# STM32L4P5 register map
File version: 1.8
CPU: CM4 r0p1, little endian, MPU, FPU, 4 interrupt priority bits
Registers are 32-bit, read-write, reset 0x0 unless marked. A register's access mark holds for its fields unless they carry their own. Offsets are from the block's base; [hi:lo] are bit positions; 'fields as' and 'values as' point back to an identical list.

## OCTOSPI1 — OctoSPI
Base 0xA0001000
Same registers: OCTOSPI2 0xA0001400
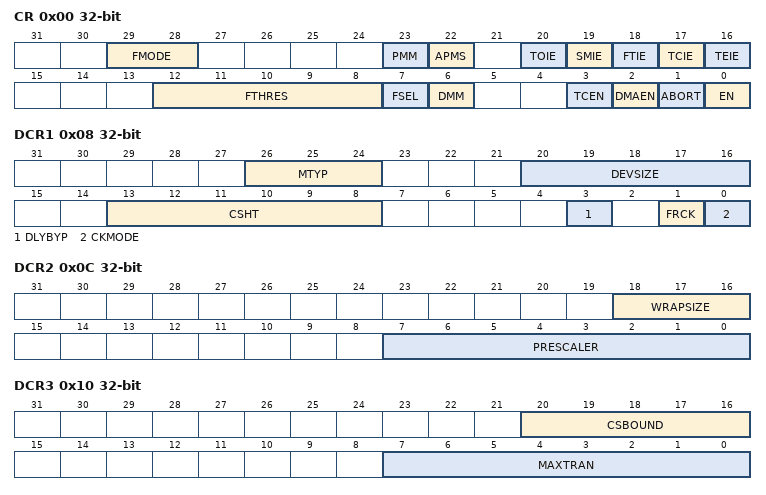
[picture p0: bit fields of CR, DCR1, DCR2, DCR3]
0x00 CR — control register
  [29:28] FMODE — Functional mode
    0=Indirect-write mode; 1=Indirect-read mode; 2=AutomaticPolling (Automatic status-polling mode); 3=Memory-mapped mode
  [23] PMM — Polling match mode
    0=AND-match mode, SMF is set if all the unmasked bits received from the device match the corresponding bits in the match register; 1=OR-match mode, SMF is set if any of the unmasked bits received from the device matches its corresponding bit in the match register
  [22] APMS — Automatic poll mode stop
    0=Running (Automatic status-polling mode is stopped only by abort or by disabling the OCTOSPI); 1=StopMatch (Automatic status-polling mode stops as soon as there is a match)
  [20] TOIE — TimeOut interrupt enable
    0=Disabled (Interrupt disabled); 1=Enabled (Interrupt enabled)
  [19] SMIE — Status match interrupt enable
    values as TOIE
  [18] FTIE — FIFO threshold interrupt enable
    values as TOIE
  [17] TCIE — Transfer complete interrupt enable
    values as TOIE
  [16] TEIE — Transfer error interrupt enable
    values as TOIE
  [12:8] FTHRES — IFO threshold level
  [7] FSEL — FLASH memory selection
    0=FLASH1 (FLASH 1 selected (data exchanged over IO[3:0])); 1=FLASH2 (FLASH 2 selected (data exchanged over IO[7:4]))
  [6] DMM — Dual-memory configuration
    0=Disabled (Dual-quad configuration disabled); 1=Enabled (Dual-quad configuration enabled)
  [3] TCEN — Timeout counter enable
    0=Disabled (Timeout counter is disabled, and thus the chip-select (NCS) remains active indefinitely after an access in Memory-mapped mode); 1=Enabled (Timeout counter is enabled, and thus the chip-select is released in the Memory-mapped mode after TIMEOUT[15:0] cycles of external device inactivity)
  [2] DMAEN — DMA enable
    0=Disabled (DMA disabled for Indirect mode); 1=Enabled (DMA enabled for Indirect mode)
  [1] ABORT — Abort request
    0=NotRequested (No abort requested); 1=Requested (Abort requested)
  [0] EN — Enable
    0=Disabled (OCTOSPI disabled); 1=Enabled (OCTOSPI enabled)
0x08 DCR1 — device configuration register
  [26:24] MTYP — Memory type
    0=Micron mode, D0/D1 ordering in DTR 8-data-bit mode. Regular-command protocol in Single-, Dual-, Quad- and Octal-SPI modes; 1=Macronix mode, D1/D0 ordering in DTR 8-data-bit mode. Regular-command protocol in Single-, Dual-, Quad- and Octal-SPI modes; 2=StandardMode; 3=Macronix RAM mode, D1/D0 ordering in DTR 8-data-bit mode. Regular-command protocol in Single-, Dual-, Quad- and Octal-SPI modes with dedicated address mapping; 4=HyperBus memory mode, the protocol follows the HyperBus specification. 8-data-bit DTR mode must be selected; 5=HyperBusMode (HyperBus register mode, addressing register space. The memory-mapped accesses in this mode must be non-cacheable, or Indirect read/write modes must be used)
  [20:16] DEVSIZE — Device size
  [13:8] CSHT — Chip-select high time
  [3] DLYBYP — Delay block bypass
    0=DelayBlockEnabled (The internal sampling clock (called feedback clock) or the DQS data strobe external signal is delayed by the delay block (for more details on this block, refer to the dedicated section of the reference manual as it is not part of the OCTOSPI peripheral)); 1=DelayBlockBypassed (The delay block is bypassed, so the internal sampling clock or the DQS data strobe external signal is not affected by the delay block. The delay is shorter than when the delay block is not bypassed, even with the delay value set to minimum value in delay block)
  [1] FRCK — Free running clock
    0=Disabled (CLK is not free running); 1=Enabled (CLK is free running (always provided))
  [0] CKMODE — Mode 0 / mode 3
    0=Mode0 (CLK must stay low while NCS is high (chip-select released). This is referred to as Mode 0); 1=Mode3 (CLK must stay high while NCS is high (chip-select released). This is referred to as Mode 3)
0x0C DCR2 — device configuration register 2
  [18:16] WRAPSIZE
    0=NoWrappingSupport (Wrapped reads are not supported by the memory); 2=WrappingSize16 (External memory supports wrap size of 16 bytes); 3=WrappingSize32 (External memory supports wrap size of 32 bytes); 4=WrappingSize64 (External memory supports wrap size of 64 bytes); 5=WrappingSize128 (External memory supports wrap size of 128 bytes)
  [7:0] PRESCALER — Clock prescaler
0x10 DCR3 — device configuration register 3
  [20:16] CSBOUND — CS boundary
  [7:0] MAXTRAN — Maximum transfer
0x14 DCR4 — device configuration register 4
  [31:0] REFRESH — Refresh rate
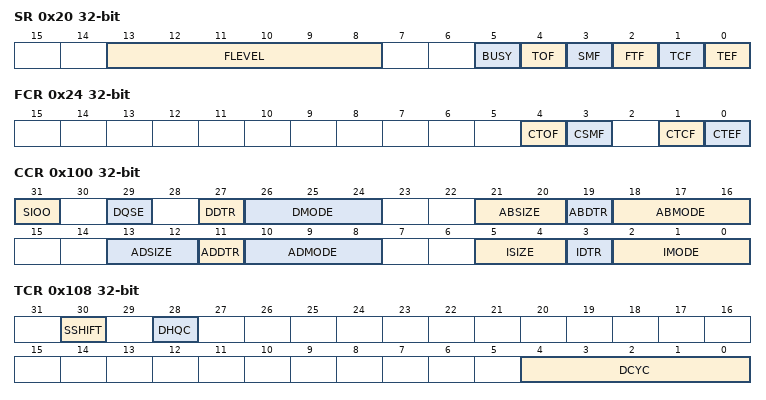
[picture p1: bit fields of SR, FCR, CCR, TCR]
0x20 SR ro — status register
  [13:8] FLEVEL — FIFO level
  [5] BUSY
    0=Cleared (This bit is cleared automatically when the operation with the external device is finished and the FIFO is empty); 1=Busy (This bit is set when an operation is ongoing)
  [4] TOF — Timeout flag
    0=Cleared (This bit is cleared by writing 1 to CTOF); 1=Timeout (This bit is set when timeout occurs)
  [3] SMF — Status match flag
    0=Cleared (It is cleared by writing 1 to CSMF); 1=Matched (This bit is set in Automatic status-polling mode when the unmasked received data matches the corresponding bits in the match register (OCTOSPI_PSMAR))
  [2] FTF — FIFO threshold flag
    0=Cleared (It is cleared automatically as soon as the threshold condition is no longer true); 1=ThresholdReached (This bit is set when the FIFO threshold has been reached)
  [1] TCF — Transfer complete flag
    0=Cleared (This bit is cleared by writing 1 to CTCF); 1=TransferCompleted (This bit is set when the programmed number of data has been transferred)
  [0] TEF — Transfer error flag
    0=Cleared (This bit is cleared by writing 1 to CTEF); 1=InvalidAddressAccessed (This bit is set in Indirect mode when an invalid address is being accessed in Indirect mode)
0x24 FCR wo — flag clear register
  [4] CTOF — Clear timeout flag
    1=Clear (Writing 1 clears the TOF flag in the OCTOSPI_SR register)
  [3] CSMF — Clear status match flag
    1=Clear (Writing 1 clears the SMF flag in the OCTOSPI_SR register)
  [1] CTCF — Clear transfer complete flag
    1=Clear (Writing 1 clears the TCF flag in the OCTOSPI_SR register)
  [0] CTEF — Clear transfer error flag
    1=Clear (Writing 1 clears the TEF flag in the OCTOSPI_SR register)
0x40 DLR — data length register
  [31:0] DL — Data length
0x48 AR — address register
  [31:0] ADDRESS
0x50 DR — data register
  [31:0] DATA
0x80 PSMKR — polling status mask register
  [31:0] MASK — Status mask
0x88 PSMAR — polling status match register
  [31:0] MATCH — Status match
0x90 PIR — polling interval register
  [15:0] INTERVAL — Polling interval
0x100 CCR — communication configuration register
  [31] SIOO — Send instruction only once mode
    0=SendEveryTransaction (Send instruction on every transaction); 1=SendOnlyFirstCmd (Send instruction only for the first command)
  [29] DQSE — DQS enable
    0=Disabled (DQS disabled); 1=Enabled (DQS enabled)
  [27] DDTR — Alternate bytes double transfer rate
    0=Disabled (DTR mode disabled for data phase); 1=Enabled (DTR mode enabled for data phase)
  [26:24] DMODE — Data mode
    0=NoData; 1=SingleLine (Data on a single line); 2=TwoLines (Data on two lines); 3=FourLines (Data on four lines); 4=EightLines (Data on eight lines)
  [21:20] ABSIZE — Alternate bytes size
    0=Bits8 (8-bit alternate bytes); 1=Bits16 (16-bit alternate bytes); 2=Bits24 (24-bit alternate bytes); 3=Bits32 (32-bit alternate bytes)
  [19] ABDTR — Alternate bytes double transfer rate
    0=Disabled (DTR mode disabled for alternate bytes phase); 1=Enabled (DTR mode enabled for alternate bytes phase)
  [18:16] ABMODE — Alternate byte mode
    0=NoAlternateBytes; 1=SingleLine (Alternate bytes on a single line); 2=TwoLines (Alternate bytes on two lines); 3=FourLines (Alternate bytes on four lines); 4=EightLines (Alternate bytes on eight lines)
  [13:12] ADSIZE — Address size
    0=Bits8 (8-bit address); 1=Bits16 (16-bit address); 2=Bits24 (24-bit address); 3=Bits32 (32-bit address)
  [11] ADDTR — Address double transfer rate
    0=Disabled (DTR mode disabled for address phase); 1=Enabled (DTR mode enabled for address phase)
  [10:8] ADMODE — Address mode
    0=NoAddress; 1=SingleLine (Address on a single line); 2=TwoLines (Address on two lines); 3=FourLines (Address on four lines); 4=EightLines (Address on eight lines)
  [5:4] ISIZE — Instruction size
    0=Bits8 (8-bit instruction); 1=Bits16 (16-bit instruction); 2=Bits24 (24-bit instruction); 3=Bits32 (32-bit instruction)
  [3] IDTR — Instruction double transfer rate
    0=Disabled (DTR mode disabled for instruction phase); 1=Enabled (DTR mode enabled for instruction phase)
  [2:0] IMODE — Instruction mode
    0=NoInstruction; 1=SingleLine (Instruction on a single line); 2=TwoLines (Instruction on two lines); 3=FourLines (Instruction on four lines); 4=EightLines (Instruction on eight lines)
0x108 TCR — timing configuration register
  [30] SSHIFT — Sample shift
    0=NoShift; 1=HalfCycleShift (1/2 cycle shift)
  [28] DHQC — Delay hold quarter cycle
    0=No delay hold; 1=QuarterCycleHold (1/4 cycle hold)
  [4:0] DCYC — Number of dummy cycles
0x110 IR — instruction register
  [31:0] INSTRUCTION
0x120 ABR — alternate bytes register
  [31:0] ALTERNATE — Alternate bytes
0x130 LPTR — low-power timeout register
  [15:0] TIMEOUT — Timeout period
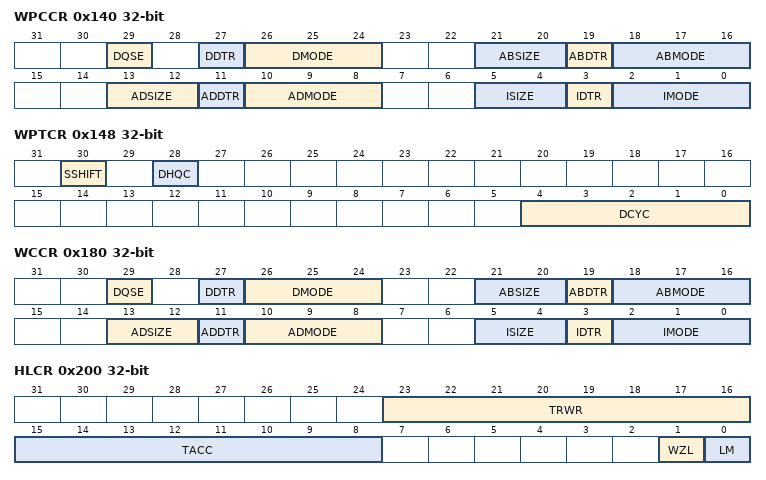
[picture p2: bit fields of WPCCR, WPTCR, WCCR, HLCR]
0x140 WPCCR access not given — wrap communication configuration register
  [29] DQSE — DQS enable
    0=Disabled (DQS disabled); 1=Enabled (DQS enabled)
  [27] DDTR — Data double transfer rate
    values as CCR.DDTR
  [26:24] DMODE — Data mode
    values as CCR.DMODE
  [21:20] ABSIZE — Alternate bytes size
    values as CCR.ABSIZE
  [19] ABDTR — Alternate bytes double transfer rate
    values as CCR.ABDTR
  [18:16] ABMODE — Alternate-byte mode
    values as CCR.ABMODE
  [13:12] ADSIZE — Address size
    values as CCR.ADSIZE
  [11] ADDTR — Address double transfer rate
    values as CCR.ADDTR
  [10:8] ADMODE — Address mode
    values as CCR.ADMODE
  [5:4] ISIZE — Instruction size
    values as CCR.ISIZE
  [3] IDTR — Instruction double transfer rate
    values as CCR.IDTR
  [2:0] IMODE — Instruction mode
    values as CCR.IMODE
0x148 WPTCR access not given — Wrap timing configuration register
  fields as TCR
0x150 WPIR access not given — Wrap instruction register
  [31:0] INSTRUCTION
0x160 WPABR access not given — Wrap alternate bytes register
  [31:0] ALTERNATE — Alternate bytes
0x180 WCCR — write communication configuration register
  [29] DQSE — DQS enable
    0=Disabled (DQS disabled); 1=Enabled (DQS enabled)
  [27] DDTR — alternate bytes double transfer rate
    values as CCR.DDTR
  [26:24] DMODE — Data mode
    values as CCR.DMODE
  [21:20] ABSIZE — Alternate bytes size
    values as CCR.ABSIZE
  [19] ABDTR — Alternate bytes double transfer rate
    values as CCR.ABDTR
  [18:16] ABMODE — Alternate byte mode
    values as CCR.ABMODE
  [13:12] ADSIZE — Address size
    values as CCR.ADSIZE
  [11] ADDTR — Address double transfer rate
    values as CCR.ADDTR
  [10:8] ADMODE — Address mode
    values as CCR.ADMODE
  [5:4] ISIZE — Instruction size
    values as CCR.ISIZE
  [3] IDTR — Instruction double transfer rate
    values as CCR.IDTR
  [2:0] IMODE — Instruction mode
    values as CCR.IMODE
0x188 WTCR — write timing configuration register
  [4:0] DCYC — Number of dummy cycles
0x190 WIR — write instruction register
  [31:0] INSTRUCTION
0x1A0 WABR — write alternate bytes register
  [31:0] ALTERNATE — Alternate bytes
0x200 HLCR — HyperBusTM latency configuration register
  [23:16] TRWR — Read write recovery time
  [15:8] TACC — Access time
  [1] WZL — Write zero latency
    0=Disabled (Latency on write accesses); 1=Enabled (No latency on write accesses)
  [0] LM — Latency mode
    0=Variable initial latency; 1=Fixed latency
